AUTOSAR XML (schema 00049)
package /AdaptiveApplicationSwComponent
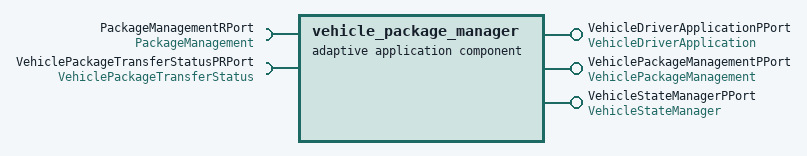
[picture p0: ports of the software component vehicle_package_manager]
  adaptive application sw component type vehicle_package_manager
    provide port VehicleDriverApplicationPPort: provided-interface=VehicleDriverApplication
    provide port VehiclePackageManagementPPort: provided-interface=VehiclePackageManagement
    require port PackageManagementRPort: required-interface=PackageManagement
    provide port VehicleStateManagerPPort: provided-interface=VehicleStateManager
    require port VehiclePackageTransferStatusPRPort: required-interface=VehiclePackageTransferStatus
package /Executables
  executable vehicle_package_manager: category=PLATFORM_LEVEL, build-type=BUILD-TYPE-DEBUG, minimum-timer-granularity=1000.0
    root sw component prototype vehicle_package_manager_root: application-type=vehicle_package_manager
package /ProcessDesign
  process design vehicle_package_manager: executable=vehicle_package_manager
